# STM32H750 register map
File version: 2.7
CPU: CM7 r0p1, little endian, MPU, FPU, 4 interrupt priority bits
Registers are 32-bit, read-write, reset 0x0 unless marked. A register's access mark holds for its fields unless they carry their own. Offsets are from the block's base; [hi:lo] are bit positions; {n}, {i} and the like mark numbered series; 'fields as' and 'values as' point back to an identical list.

## OTG1_HS_PWRCLK — USB 1 on the go high speed
Base 0x40040E00
Same registers: OTG2_HS_PWRCLK 0x40080E00
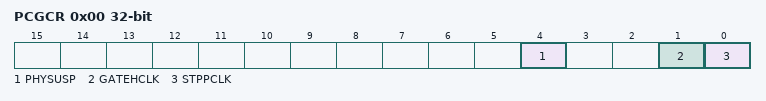
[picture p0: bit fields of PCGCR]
0x00 PCGCR — Power and clock gating control register
  [4] PHYSUSP — PHY suspended
  [1] GATEHCLK
  [0] STPPCLK — Stop PHY clock

## CAN_CCU — CCU registers
Base 0x4000A800
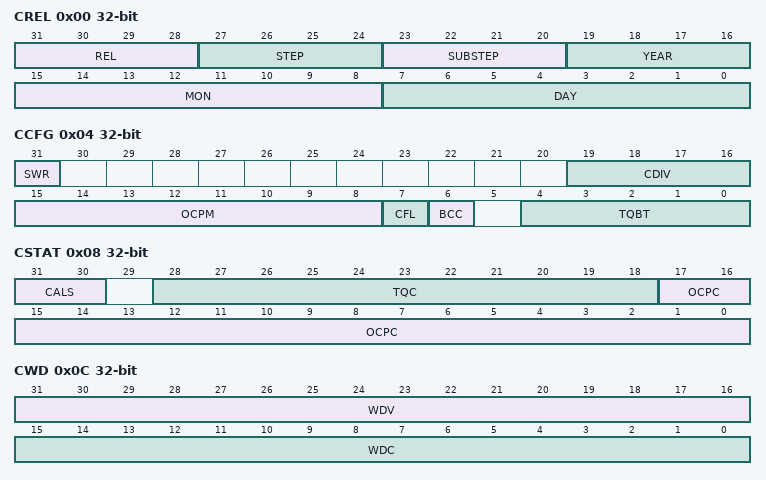
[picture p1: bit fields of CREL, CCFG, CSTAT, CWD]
0x00 CREL — Clock Calibration Unit Core Release Register
  [31:28] REL — Core Release
  [27:24] STEP — Step of Core Release
  [23:20] SUBSTEP — Sub-step of Core Release
  [19:16] YEAR — Time Stamp Year
  [15:8] MON — Time Stamp Month
  [7:0] DAY — Time Stamp Day
0x04 CCFG — Calibration Configuration Register
  [31] SWR — Software Reset
  [19:16] CDIV — Clock Divider
  [15:8] OCPM — Oscillator Clock Periods Minimum
  [7] CFL — Calibration Field Length
  [6] BCC — Bypass Clock Calibration
  [4:0] TQBT — Time Quanta per Bit Time
0x08 CSTAT — Calibration Status Register
  [31:30] CALS — Calibration State
  [28:18] TQC — Time Quanta Counter
  [17:0] OCPC — Oscillator Clock Period Counter
0x0C CWD — Calibration Watchdog Register
  [31:16] WDV, [15:0] WDC
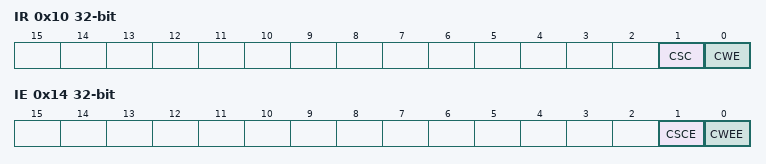
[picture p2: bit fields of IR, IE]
0x10 IR — Clock Calibration Unit Interrupt Register
  [1] CSC — Calibration State Changed
  [0] CWE — Calibration Watchdog Event
0x14 IE — Clock Calibration Unit Interrupt Enable Register
  [1] CSCE — Calibration State Changed Enable
  [0] CWEE — Calibration Watchdog Event Enable

## MDIOS — Management data input/output slave
Base 0x40009400
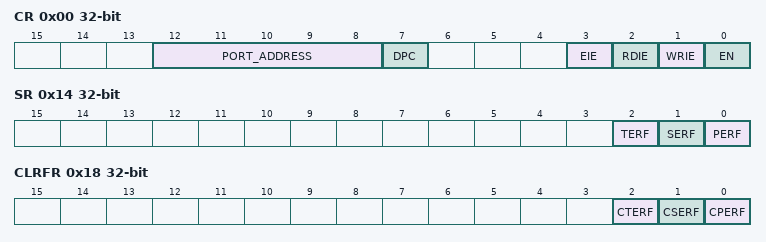
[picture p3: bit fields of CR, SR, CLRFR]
0x00 CR — MDIOS configuration register
  [12:8] PORT_ADDRESS — Slaves's address
  [7] DPC — Disable Preamble Check
  [3] EIE — Error interrupt enable
  [2] RDIE — Register Read Interrupt Enable
  [1] WRIE — Register write interrupt enable
  [0] EN — Peripheral enable
0x04 WRFR ro — MDIOS write flag register
  [31:0] WRF — Write flags for MDIO registers 0 to 31
0x08 CWRFR — MDIOS clear write flag register
  [31:0] CWRF — Clear the write flag
0x0C RDFR ro — MDIOS read flag register
  [31:0] RDF — Read flags for MDIO registers 0 to 31
0x10 CRDFR — MDIOS clear read flag register
  [31:0] CRDF — Clear the read flag
0x14 SR ro — MDIOS status register
  [2] TERF — Turnaround error flag
  [1] SERF — Start error flag
  [0] PERF — Preamble error flag
0x18 CLRFR — MDIOS clear flag register
  [2] CTERF — Clear the turnaround error flag
  [1] CSERF — Clear the start error flag
  [0] CPERF — Clear the preamble error flag
{0x1C+4i} DINR{i} ro (i=0..31) — MDIOS input data register {i}
  [15:0] DIN{i} — Input data received from MDIO Master during write frames
{0x9C+4i} DOUTR{i} (i=0..31) — MDIOS output data register {i}
  [15:0] DOUT{i} — Output data sent to MDIO Master during read frames

## OPAMP — Operational amplifiers
Base 0x40009000
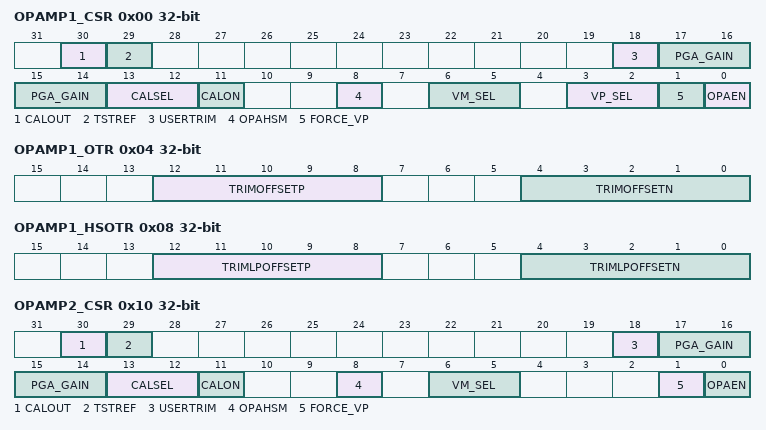
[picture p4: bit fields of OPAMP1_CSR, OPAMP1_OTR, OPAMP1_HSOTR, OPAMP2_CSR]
0x00 OPAMP1_CSR — OPAMP1 control/status register
  [30] CALOUT — Operational amplifier calibration output
  [29] TSTREF — OPAMP calibration reference voltage output control (reserved for test)
  [18] USERTRIM — User trimming enable
  [17:14] PGA_GAIN — allows to switch from AOP offset trimmed values to AOP offset
  [13:12] CALSEL — Calibration selection
  [11] CALON — Calibration mode enabled
  [8] OPAHSM — Operational amplifier high-speed mode
  [6:5] VM_SEL — Inverting input selection
  [3:2] VP_SEL — Operational amplifier PGA mode
  [1] FORCE_VP — Force internal reference on VP (reserved for test
  [0] OPAEN — Operational amplifier Enable
0x04 OPAMP1_OTR — OPAMP1 offset trimming register in normal mode
  [12:8] TRIMOFFSETP — Trim for PMOS differential pairs
  [4:0] TRIMOFFSETN — Trim for NMOS differential pairs
0x08 OPAMP1_HSOTR — OPAMP1 offset trimming register in low-power mode
  [12:8] TRIMLPOFFSETP — Trim for PMOS differential pairs
  [4:0] TRIMLPOFFSETN — Trim for NMOS differential pairs
0x10 OPAMP2_CSR — OPAMP2 control/status register
  [30] CALOUT — Operational amplifier calibration output
  [29] TSTREF — OPAMP calibration reference voltage output control (reserved for test)
  [18] USERTRIM — User trimming enable
  [17:14] PGA_GAIN — Operational amplifier Programmable amplifier gain value
  [13:12] CALSEL — Calibration selection
  [11] CALON — Calibration mode enabled
  [8] OPAHSM — Operational amplifier high-speed mode
  [6:5] VM_SEL — Inverting input selection
  [1] FORCE_VP — Force internal reference on VP (reserved for test)
  [0] OPAEN — Operational amplifier Enable
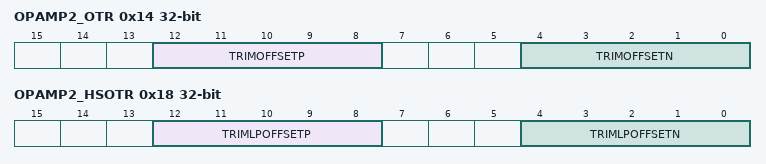
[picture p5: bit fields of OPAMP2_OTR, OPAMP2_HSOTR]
0x14 OPAMP2_OTR — OPAMP2 offset trimming register in normal mode
  fields as OPAMP1_OTR
0x18 OPAMP2_HSOTR — OPAMP2 offset trimming register in low-power mode
  fields as OPAMP1_HSOTR
